# HC32F334JATI register map
File version: 1.0
CPU: CM4 r0p1, little endian, MPU, FPU, 4 interrupt priority bits
Registers are 32-bit, read-write, reset 0x0 unless marked. A register's access mark holds for its fields unless they carry their own. Offsets are from the block's base; [hi:lo] are bit positions; {n}, {i} and the like mark numbered series.

## ADC1
Base 0x40040000
0x00 STR 8-bit
  [0] STRT
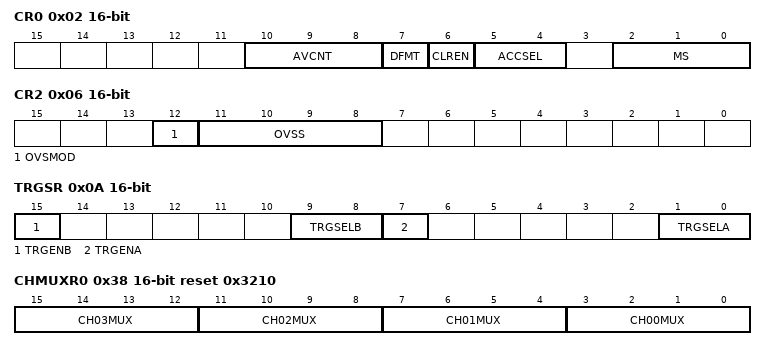
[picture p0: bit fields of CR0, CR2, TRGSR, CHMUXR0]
0x02 CR0 16-bit
  [10:8] AVCNT, [7] DFMT, [6] CLREN, [5:4] ACCSEL, [2:0] MS
0x04 CR1 16-bit
  [2] RSCHSEL
0x06 CR2 16-bit
  [12] OVSMOD, [11:8] OVSS
0x0A TRGSR 16-bit
  [15] TRGENB, [9:8] TRGSELB, [7] TRGENA, [1:0] TRGSELA
0x0C CHSELRA
  [15:0] CHSELA
0x10 CHSELRB
  [15:0] CHSELB
0x14 AVCHSELR
  [15:0] AVCHSEL
0x18 EXCHSELR 8-bit
  [0] EXCHSEL
{0x20+i} SSTR{i} 8-bit reset 0xB (i=0..15)
0x38 CHMUXR0 16-bit reset 0x3210
  [4n+3:4n] CH{n:02}MUX (n=0..3)
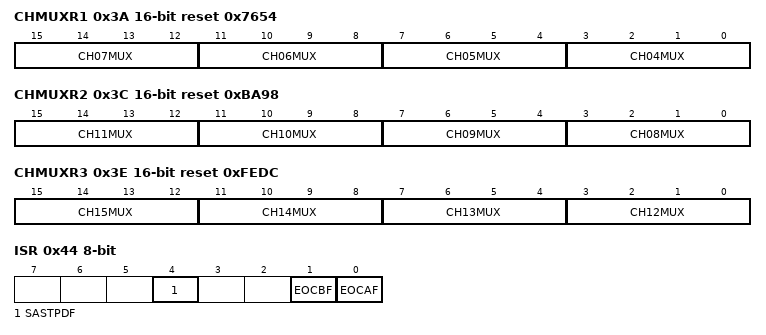
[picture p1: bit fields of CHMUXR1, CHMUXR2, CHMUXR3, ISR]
0x3A CHMUXR1 16-bit reset 0x7654
  [4n-13:4n-16] CH{n:02}MUX (n=4..7)
0x3C CHMUXR2 16-bit reset 0xBA98
  [4n-29:4n-32] CH{n:02}MUX (n=8..11)
0x3E CHMUXR3 16-bit reset 0xFEDC
  [4n-45:4n-48] CH{n}MUX (n=12..15)
0x44 ISR 8-bit ro
  [4] SASTPDF, [1] EOCBF, [0] EOCAF
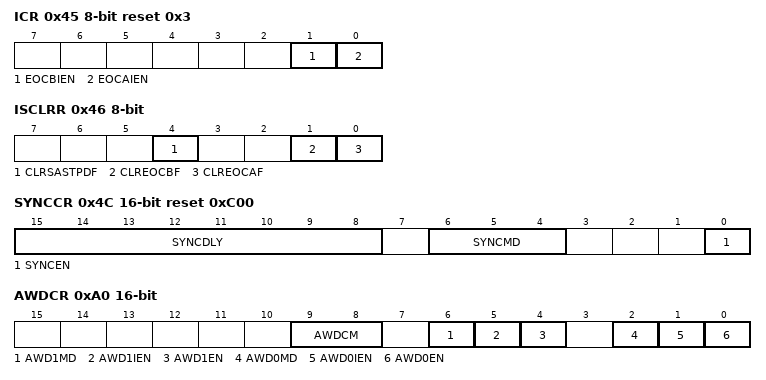
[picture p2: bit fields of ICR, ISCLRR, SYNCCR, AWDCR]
0x45 ICR 8-bit reset 0x3
  [1] EOCBIEN, [0] EOCAIEN
0x46 ISCLRR 8-bit wo
  [4] CLRSASTPDF, [1] CLREOCBF, [0] CLREOCAF
0x4C SYNCCR 16-bit reset 0xC00
  [15:8] SYNCDLY, [6:4] SYNCMD, [0] SYNCEN
{0x50+2i} DR{i} 16-bit ro (i=0..15)
0xA0 AWDCR 16-bit
  [9:8] AWDCM, [6] AWD1MD, [5] AWD1IEN, [4] AWD1EN, [2] AWD0MD, [1] AWD0IEN, [0] AWD0EN
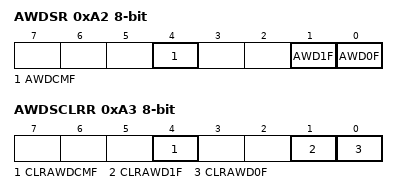
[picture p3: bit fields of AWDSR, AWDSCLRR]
0xA2 AWDSR 8-bit ro
  [4] AWDCMF, [1] AWD1F, [0] AWD0F
0xA3 AWDSCLRR 8-bit wo
  [4] CLRAWDCMF, [1] CLRAWD1F, [0] CLRAWD0F
0xA4 AWD0DR0 16-bit
0xA6 AWD0DR1 16-bit reset 0xFFFF
0xA8 AWD0CHSR 8-bit
  [4:0] AWDCH
0xAC AWD1DR0 16-bit
0xAE AWD1DR1 16-bit reset 0xFFFF
0xB0 AWD1CHSR 8-bit
  [4:0] AWDCH

## ADC2
Base 0x40040400
Registers as ADC1, without SYNCCR.

## ADC3
Base 0x40040800
Registers as ADC1, without SSTR{n} (n=12..15), CHMUXR3, SYNCCR, DR{n} (n=12..15); these are added or differ:
0x0C CHSELRA
  [11:0] CHSELA
0x10 CHSELRB
  [11:0] CHSELB
0x14 AVCHSELR
  [11:0] AVCHSEL

## AOS
Base 0x40010800
0x00 INTSFTTRG wo
  [0] STRG
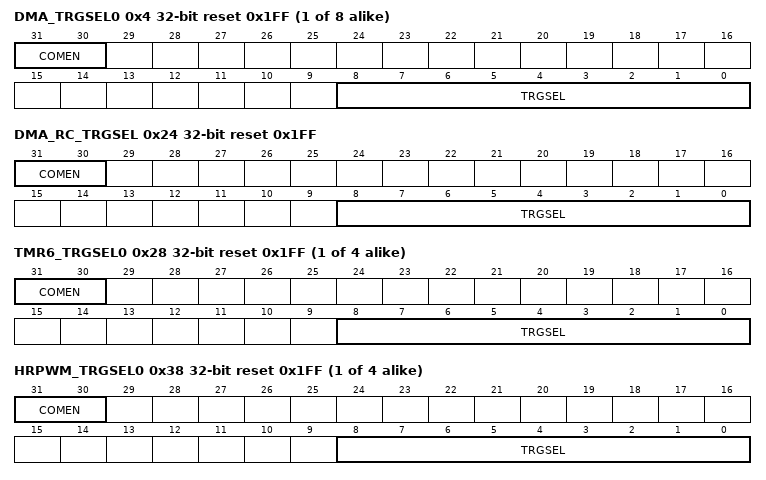
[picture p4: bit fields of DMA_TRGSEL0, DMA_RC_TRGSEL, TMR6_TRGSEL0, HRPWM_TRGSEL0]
{0x4+4i} DMA_TRGSEL{i} reset 0x1FF (i=0..7)
  [31:30] COMEN, [8:0] TRGSEL
0x24 DMA_RC_TRGSEL reset 0x1FF
  [31:30] COMEN, [8:0] TRGSEL
{0x28+4i} TMR6_TRGSEL{i} reset 0x1FF (i=0..3)
  [31:30] COMEN, [8:0] TRGSEL
{0x38+4i} HRPWM_TRGSEL{i} reset 0x1FF (i=0..3)
  [31:30] COMEN, [8:0] TRGSEL
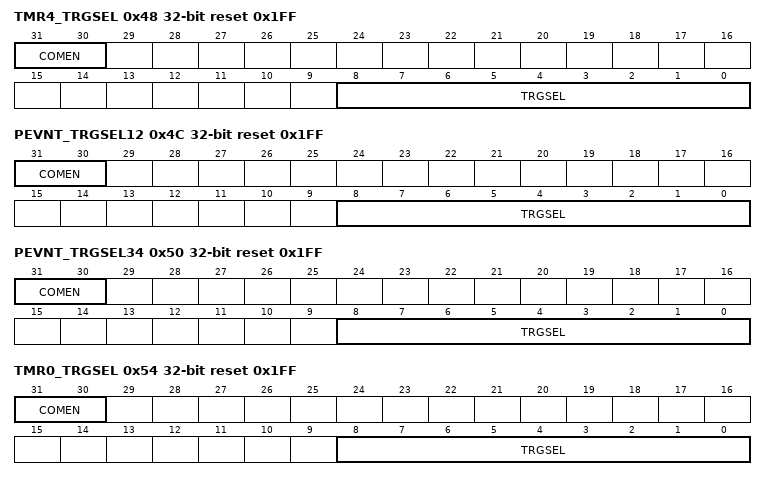
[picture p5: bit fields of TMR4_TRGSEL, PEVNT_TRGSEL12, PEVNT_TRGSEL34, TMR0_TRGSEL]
0x48 TMR4_TRGSEL reset 0x1FF
  [31:30] COMEN, [8:0] TRGSEL
0x4C PEVNT_TRGSEL12 reset 0x1FF
  [31:30] COMEN, [8:0] TRGSEL
0x50 PEVNT_TRGSEL34 reset 0x1FF
  [31:30] COMEN, [8:0] TRGSEL
0x54 TMR0_TRGSEL reset 0x1FF
  [31:30] COMEN, [8:0] TRGSEL
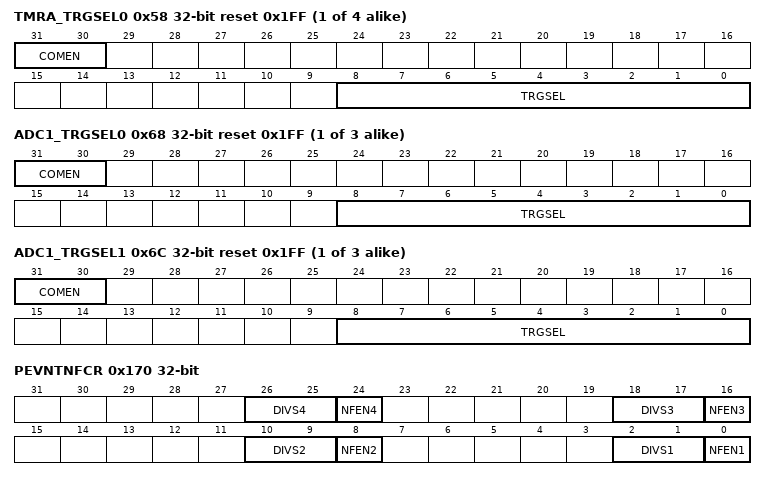
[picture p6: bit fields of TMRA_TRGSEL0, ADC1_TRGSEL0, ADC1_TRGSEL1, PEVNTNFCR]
{0x58+4i} TMRA_TRGSEL{i} reset 0x1FF (i=0..3)
  [31:30] COMEN, [8:0] TRGSEL
{0x60+8i} ADC{i}_TRGSEL0 reset 0x1FF (i=1..3)
  [31:30] COMEN, [8:0] TRGSEL
{0x64+8i} ADC{i}_TRGSEL1 reset 0x1FF (i=1..3)
  [31:30] COMEN, [8:0] TRGSEL
0x80 COMTRGSEL1 reset 0x1FF
  [8:0] TRGSEL
0x84 COMTRGSEL2 reset 0x1FF
  [8:0] TRGSEL
{0xE4+0x1C*i} PEVNTDIRR{i} (i=1..4)
  [15:0] PDIR
{0xE8+0x1C*i} PEVNTIDR{i} ro (i=1..4)
  [15:0] PIN
{0xEC+0x1C*i} PEVNTODR{i} (i=1..4)
  [15:0] POUT
{0xF0+0x1C*i} PEVNTORR{i} (i=1..4)
  [15:0] POR
{0xF4+0x1C*i} PEVNTOSR{i} (i=1..4)
  [15:0] POS
{0xF8+0x1C*i} PEVNTRISR{i} (i=1..4)
  [15:0] RIS
{0xFC+0x1C*i} PEVNTFALR{i} (i=1..4)
  [15:0] FAL
0x170 PEVNTNFCR
  [8n-6:8n-7] DIVS{n} (n=1..4), [8n-8] NFEN{n} (n=1..4)

## CMP1 — desc CMP
Base 0x40038400
Same registers: CMP2 0x40038500, CMP3 0x4003B000
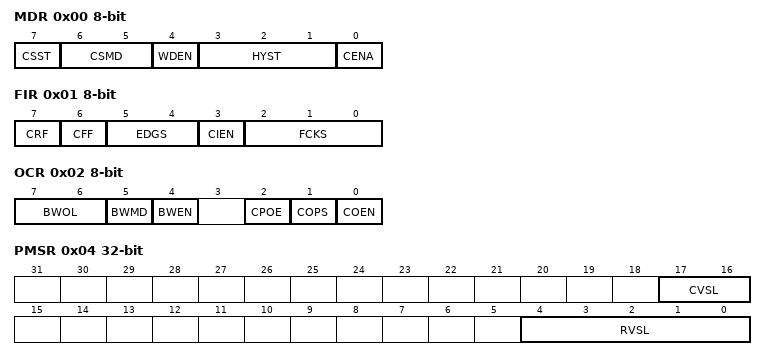
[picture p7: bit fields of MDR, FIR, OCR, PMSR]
0x00 MDR 8-bit
  [7] CSST, [6:5] CSMD, [4] WDEN, [3:1] HYST, [0] CENA
0x01 FIR 8-bit
  [7] CRF, [6] CFF, [5:4] EDGS, [3] CIEN, [2:0] FCKS
0x02 OCR 8-bit
  [7:6] BWOL, [5] BWMD, [4] BWEN, [2] CPOE, [1] COPS, [0] COEN
0x03 OMR 8-bit ro
  [0] CMON
0x04 PMSR
  [17:16] CVSL, [4:0] RVSL
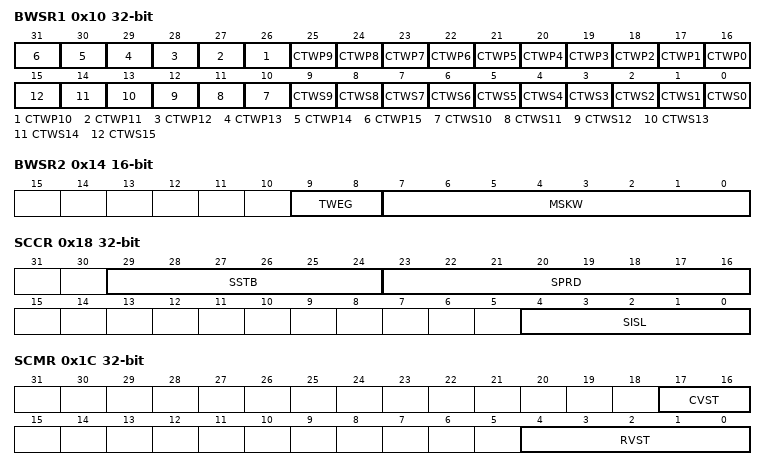
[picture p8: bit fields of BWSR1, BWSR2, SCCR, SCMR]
0x10 BWSR1
  [n+16] CTWP{n} (n=0..15), [n] CTWS{n} (n=0..15)
0x14 BWSR2 16-bit
  [9:8] TWEG, [7:0] MSKW
0x18 SCCR
  [29:24] SSTB, [23:16] SPRD, [4:0] SISL
0x1C SCMR
  [17:16] CVST, [4:0] RVST

## CMU
Base 0x40048000
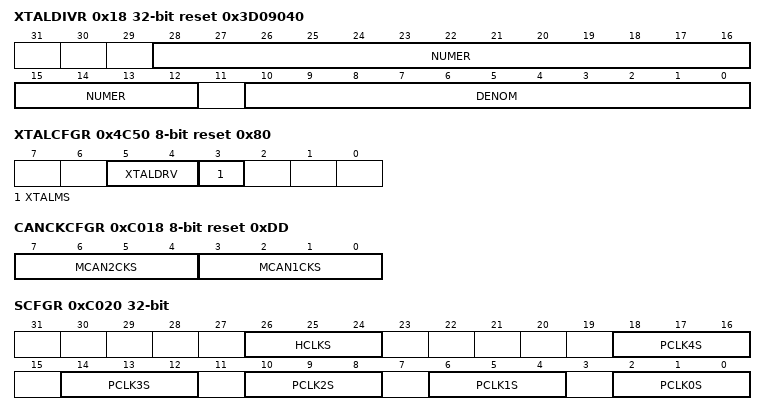
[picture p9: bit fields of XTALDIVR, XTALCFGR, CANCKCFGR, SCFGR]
0x18 XTALDIVR reset 0x3D09040
  [28:12] NUMER, [10:0] DENOM
0x1C XTALDIVCR
  [0] FRADIVEN
0x4C50 XTALCFGR 8-bit reset 0x80
  [5:4] XTALDRV, [3] XTALMS
0x4C54 XTAL32CR 8-bit
  [0] XTAL32STP
0x4C58 XTAL32CFGR 8-bit
  [2:0] XTAL32DRV
0x4C68 XTAL32NFR 8-bit
  [1:0] XTAL32NF
0x4C6C LRCCR 8-bit
  [0] LRCSTP
0x4C74 LRCTRM 8-bit
0xC010 PERICKSEL 16-bit
  [3:0] PERICKSEL
0xC018 CANCKCFGR 8-bit reset 0xDD
  [7:4] MCAN2CKS, [3:0] MCAN1CKS
0xC020 SCFGR
  [26:24] HCLKS, [4n+2:4n] PCLK{n}S (n=0..4)
0xC026 CKSWR 8-bit reset 0x1
  [2:0] CKSW
0xC02A PLLHCR 8-bit reset 0x1
  [0] PLLHOFF
0xC032 XTALCR 8-bit reset 0x1
  [0] XTALSTP
0xC036 HRCCR 8-bit reset 0x1
  [0] HRCSTP
0xC038 MRCCR 8-bit reset 0x80
  [0] MRCSTP
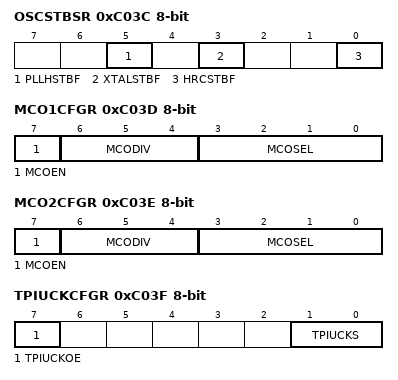
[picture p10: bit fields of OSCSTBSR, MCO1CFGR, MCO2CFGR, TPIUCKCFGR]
0xC03C OSCSTBSR 8-bit
  [5] PLLHSTBF, [3] XTALSTBF, [0] HRCSTBF
0xC03D MCO1CFGR 8-bit
  [7] MCOEN, [6:4] MCODIV, [3:0] MCOSEL
0xC03E MCO2CFGR 8-bit
  [7] MCOEN, [6:4] MCODIV, [3:0] MCOSEL
0xC03F TPIUCKCFGR 8-bit
  [7] TPIUCKOE, [1:0] TPIUCKS
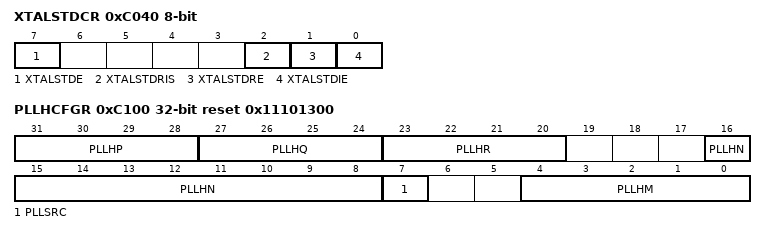
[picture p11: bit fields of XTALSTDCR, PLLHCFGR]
0xC040 XTALSTDCR 8-bit
  [7] XTALSTDE, [2] XTALSTDRIS, [1] XTALSTDRE, [0] XTALSTDIE
0xC041 XTALSTDSR 8-bit
  [0] XTALSTDF
0xC061 MRCTRM 8-bit
0xC062 HRCTRM 8-bit
0xC0A2 XTALSTBCR 8-bit reset 0x5
  [3:0] XTALSTB
0xC100 PLLHCFGR reset 0x11101300
  [31:28] PLLHP, [27:24] PLLHQ, [23:20] PLLHR, [16:8] PLLHN, [7] PLLSRC, [4:0] PLLHM
